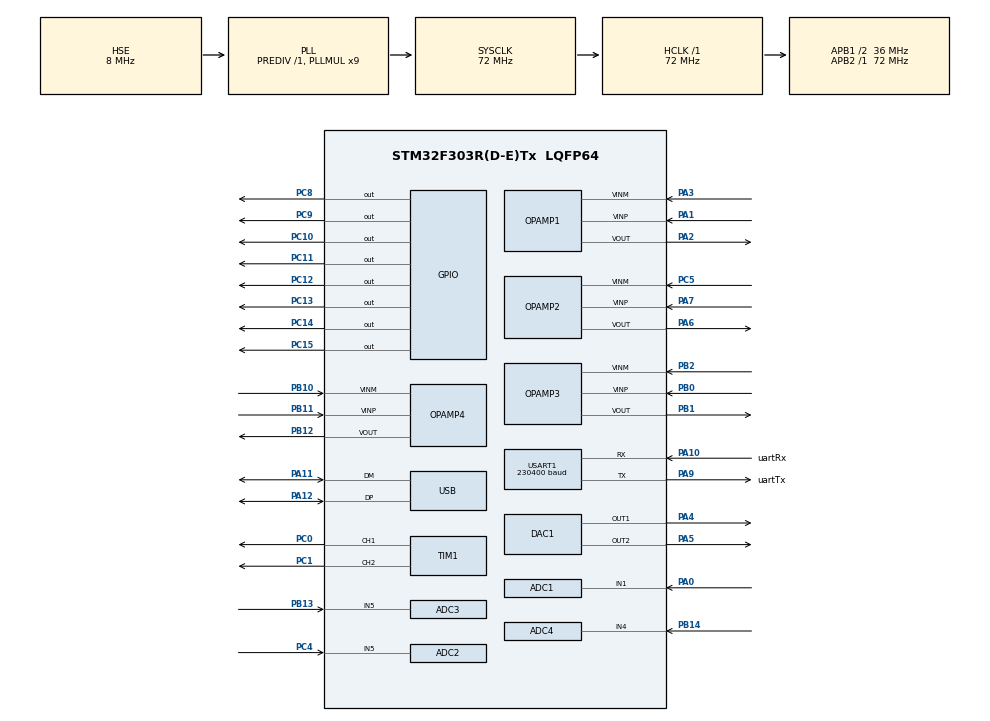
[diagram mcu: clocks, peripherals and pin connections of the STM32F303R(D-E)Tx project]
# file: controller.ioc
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ADC1.AWD1HighThreshold=2500
ADC1.AWD1ITMode=ENABLE
ADC1.AWD1LowThreshold=1500
ADC1.Channel-0\#ChannelRegularConversion=ADC_CHANNEL_3
ADC1.ClockPrescaler=ADC_CLOCK_SYNC_PCLK_DIV1
ADC1.ContinuousConvMode=DISABLE
ADC1.DMAContinuousRequests=ENABLE
ADC1.DataAlign=ADC_DATAALIGN_RIGHT
ADC1.DiscontinuousConvMode=DISABLE
ADC1.EOCSelection=ADC_EOC_SINGLE_CONV
ADC1.EnableAnalogWatchDog1=true
ADC1.EnableAnalogWatchDog2=false
ADC1.EnableAnalogWatchDog3=false
ADC1.EnableInjectedConversion=ENABLE
ADC1.EnableRegularConversion=ENABLE
ADC1.ExternalTrigConv=ADC_EXTERNALTRIGCONV_T3_TRGO
ADC1.ExternalTrigConvEdge=ADC_EXTERNALTRIGCONVEDGE_RISING
ADC1.InjNumberOfConversion=0
ADC1.LowPowerAutoWait=DISABLE
ADC1.NbrOfConversion=1
ADC1.NbrOfConversionFlag=1
ADC1.Offset-0\#ChannelRegularConversion=0
ADC1.OffsetNumber-0\#ChannelRegularConversion=ADC_OFFSET_NONE
ADC1.Overrun=ADC_OVR_DATA_OVERWRITTEN
ADC1.Rank-0\#ChannelRegularConversion=1
ADC1.Resolution=ADC_RESOLUTION_12B
ADC1.SamplingTime-0\#ChannelRegularConversion=ADC_SAMPLETIME_181CYCLES_5
ADC1.ScanConvMode=ADC_SCAN_DISABLE
ADC1.WatchdogChannel=ADC_CHANNEL_3
ADC1.WatchdogMode=ADC_ANALOGWATCHDOG_SINGLE_REG
ADC1.master=1
ADC2.AWD1HighThreshold=2500
ADC2.AWD1ITMode=ENABLE
ADC2.AWD1LowThreshold=1500
ADC2.Channel-0\#ChannelRegularConversion=ADC_CHANNEL_3
ADC2.ClockPrescaler=ADC_CLOCK_SYNC_PCLK_DIV1
ADC2.ContinuousConvMode=DISABLE
ADC2.DMAContinuousRequests=ENABLE
ADC2.DataAlign=ADC_DATAALIGN_RIGHT
ADC2.DiscontinuousConvMode=DISABLE
ADC2.EOCSelection=ADC_EOC_SINGLE_CONV
ADC2.EnableAnalogWatchDog1=true
ADC2.EnableAnalogWatchDog2=false
ADC2.EnableAnalogWatchDog3=false
ADC2.EnableInjectedConversion=ENABLE
ADC2.EnableRegularConversion=ENABLE
ADC2.ExternalTrigConv=ADC_EXTERNALTRIGCONV_T3_TRGO
ADC2.ExternalTrigConvEdge=ADC_EXTERNALTRIGCONVEDGE_RISING
ADC2.InjNumberOfConversion=0
ADC2.LowPowerAutoWait=DISABLE
ADC2.NbrOfConversion=1
ADC2.NbrOfConversionFlag=1
ADC2.Offset-0\#ChannelRegularConversion=0
ADC2.OffsetNumber-0\#ChannelRegularConversion=ADC_OFFSET_NONE
ADC2.Overrun=ADC_OVR_DATA_OVERWRITTEN
ADC2.Rank-0\#ChannelRegularConversion=1
ADC2.Resolution=ADC_RESOLUTION_12B
ADC2.SamplingTime-0\#ChannelRegularConversion=ADC_SAMPLETIME_181CYCLES_5
ADC2.ScanConvMode=ADC_SCAN_DISABLE
ADC2.WatchdogChannel=ADC_CHANNEL_3
ADC2.WatchdogMode=ADC_ANALOGWATCHDOG_SINGLE_REG
ADC3.AWD1HighThreshold=2500
ADC3.AWD1ITMode=ENABLE
ADC3.AWD1LowThreshold=1500
ADC3.Channel-44\#ChannelRegularConversion=ADC_CHANNEL_1
ADC3.ClockPrescaler=ADC_CLOCK_ASYNC_DIV1
ADC3.ContinuousConvMode=DISABLE
ADC3.DMAContinuousRequests=ENABLE
ADC3.DataAlign=ADC_DATAALIGN_RIGHT
ADC3.DiscontinuousConvMode=DISABLE
ADC3.EOCSelection=ADC_EOC_SINGLE_CONV
ADC3.EnableAnalogWatchDog1=true
ADC3.EnableAnalogWatchDog2=false
ADC3.EnableAnalogWatchDog3=false
ADC3.EnableInjectedConversion=ENABLE
ADC3.EnableRegularConversion=ENABLE
ADC3.ExternalTrigConv=ADC_EXTERNALTRIGCONV_T3_TRGO
ADC3.ExternalTrigConvEdge=ADC_EXTERNALTRIGCONVEDGE_RISING
ADC3.InjNumberOfConversion=0
ADC3.LowPowerAutoWait=DISABLE
ADC3.NbrOfConversion=1
ADC3.NbrOfConversionFlag=1
ADC3.Offset-44\#ChannelRegularConversion=0
ADC3.OffsetNumber-44\#ChannelRegularConversion=ADC_OFFSET_NONE
ADC3.Overrun=ADC_OVR_DATA_OVERWRITTEN
ADC3.Rank-44\#ChannelRegularConversion=1
ADC3.Resolution=ADC_RESOLUTION_12B
ADC3.SamplingTime-44\#ChannelRegularConversion=ADC_SAMPLETIME_181CYCLES_5
ADC3.ScanConvMode=ADC_SCAN_DISABLE
ADC3.WatchdogChannel=ADC_CHANNEL_1
ADC3.WatchdogMode=ADC_ANALOGWATCHDOG_SINGLE_REG
ADC3.master=1
ADC4.AWD1HighThreshold=2500
ADC4.AWD1ITMode=ENABLE
ADC4.AWD1LowThreshold=1500
ADC4.Channel-56\#ChannelRegularConversion=ADC_CHANNEL_3
ADC4.ClockPrescaler=ADC_CLOCK_ASYNC_DIV1
ADC4.ContinuousConvMode=DISABLE
ADC4.DMAContinuousRequests=ENABLE
ADC4.DataAlign=ADC_DATAALIGN_RIGHT
ADC4.DiscontinuousConvMode=DISABLE
ADC4.EOCSelection=ADC_EOC_SINGLE_CONV
ADC4.EnableAnalogWatchDog1=true
ADC4.EnableAnalogWatchDog2=false
ADC4.EnableAnalogWatchDog3=false
ADC4.EnableInjectedConversion=ENABLE
ADC4.EnableRegularConversion=ENABLE
ADC4.ExternalTrigConv=ADC_EXTERNALTRIGCONV_T3_TRGO
ADC4.ExternalTrigConvEdge=ADC_EXTERNALTRIGCONVEDGE_RISING
ADC4.InjNumberOfConversion=0
ADC4.LowPowerAutoWait=DISABLE
ADC4.NbrOfConversion=1
ADC4.NbrOfConversionFlag=1
ADC4.Offset-56\#ChannelRegularConversion=0
ADC4.OffsetNumber-56\#ChannelRegularConversion=ADC_OFFSET_NONE
ADC4.Overrun=ADC_OVR_DATA_OVERWRITTEN
ADC4.Rank-56\#ChannelRegularConversion=1
ADC4.Resolution=ADC_RESOLUTION_12B
ADC4.SamplingTime-56\#ChannelRegularConversion=ADC_SAMPLETIME_181CYCLES_5
ADC4.ScanConvMode=ADC_SCAN_DISABLE
ADC4.WatchdogChannel=ADC_CHANNEL_3
ADC4.WatchdogMode=ADC_ANALOGWATCHDOG_SINGLE_REG
Dma.ADC1.6.Direction=DMA_PERIPH_TO_MEMORY
Dma.ADC1.6.Instance=DMA1_Channel1
Dma.ADC1.6.MemDataAlignment=DMA_MDATAALIGN_HALFWORD
Dma.ADC1.6.MemInc=DMA_MINC_ENABLE
Dma.ADC1.6.Mode=DMA_CIRCULAR
Dma.ADC1.6.PeriphDataAlignment=DMA_PDATAALIGN_HALFWORD
Dma.ADC1.6.PeriphInc=DMA_PINC_DISABLE
Dma.ADC1.6.Priority=DMA_PRIORITY_MEDIUM
Dma.ADC2.5.Direction=DMA_PERIPH_TO_MEMORY
Dma.ADC2.5.Instance=DMA2_Channel1
Dma.ADC2.5.MemDataAlignment=DMA_MDATAALIGN_HALFWORD
Dma.ADC2.5.MemInc=DMA_MINC_ENABLE
Dma.ADC2.5.Mode=DMA_CIRCULAR
Dma.ADC2.5.PeriphDataAlignment=DMA_PDATAALIGN_HALFWORD
Dma.ADC2.5.PeriphInc=DMA_PINC_DISABLE
Dma.ADC2.5.Priority=DMA_PRIORITY_MEDIUM
Dma.ADC3.4.Direction=DMA_PERIPH_TO_MEMORY
Dma.ADC3.4.Instance=DMA2_Channel5
Dma.ADC3.4.MemDataAlignment=DMA_MDATAALIGN_HALFWORD
Dma.ADC3.4.MemInc=DMA_MINC_ENABLE
Dma.ADC3.4.Mode=DMA_CIRCULAR
Dma.ADC3.4.PeriphDataAlignment=DMA_PDATAALIGN_HALFWORD
Dma.ADC3.4.PeriphInc=DMA_PINC_DISABLE
Dma.ADC3.4.Priority=DMA_PRIORITY_MEDIUM
Dma.ADC4.3.Direction=DMA_PERIPH_TO_MEMORY
Dma.ADC4.3.Instance=DMA2_Channel2
Dma.ADC4.3.MemDataAlignment=DMA_MDATAALIGN_HALFWORD
Dma.ADC4.3.MemInc=DMA_MINC_ENABLE
Dma.ADC4.3.Mode=DMA_CIRCULAR
Dma.ADC4.3.PeriphDataAlignment=DMA_PDATAALIGN_HALFWORD
Dma.ADC4.3.PeriphInc=DMA_PINC_DISABLE
Dma.ADC4.3.Priority=DMA_PRIORITY_MEDIUM
Dma.MEMTOMEM.0.Direction=DMA_MEMORY_TO_MEMORY
Dma.MEMTOMEM.0.Instance=DMA1_Channel2
Dma.MEMTOMEM.0.MemDataAlignment=DMA_MDATAALIGN_BYTE
Dma.MEMTOMEM.0.MemInc=DMA_MINC_ENABLE
Dma.MEMTOMEM.0.Mode=DMA_NORMAL
Dma.MEMTOMEM.0.PeriphDataAlignment=DMA_PDATAALIGN_BYTE
Dma.MEMTOMEM.0.PeriphInc=DMA_PINC_ENABLE
Dma.MEMTOMEM.0.Priority=DMA_PRIORITY_LOW
Dma.Request0=MEMTOMEM
Dma.Request1=USART1_TX
Dma.Request2=USART1_RX
Dma.Request3=ADC4
Dma.Request4=ADC3
Dma.Request5=ADC2
Dma.Request6=ADC1
Dma.Request7=TIM4_UP
Dma.TIM4_UP.7.Direction=DMA_MEMORY_TO_PERIPH
Dma.TIM4_UP.7.Instance=DMA1_Channel7
Dma.TIM4_UP.7.MemDataAlignment=DMA_MDATAALIGN_BYTE
Dma.TIM4_UP.7.MemInc=DMA_MINC_ENABLE
Dma.TIM4_UP.7.Mode=DMA_NORMAL
Dma.TIM4_UP.7.PeriphDataAlignment=DMA_PDATAALIGN_BYTE
Dma.TIM4_UP.7.PeriphInc=DMA_PINC_DISABLE
Dma.TIM4_UP.7.Priority=DMA_PRIORITY_VERY_HIGH
Dma.USART1_RX.2.Direction=DMA_PERIPH_TO_MEMORY
Dma.USART1_RX.2.Instance=DMA1_Channel5
Dma.USART1_RX.2.MemDataAlignment=DMA_MDATAALIGN_BYTE
Dma.USART1_RX.2.MemInc=DMA_MINC_ENABLE
Dma.USART1_RX.2.Mode=DMA_NORMAL
Dma.USART1_RX.2.PeriphDataAlignment=DMA_PDATAALIGN_BYTE
Dma.USART1_RX.2.PeriphInc=DMA_PINC_DISABLE
Dma.USART1_RX.2.Priority=DMA_PRIORITY_LOW
Dma.USART1_TX.1.Direction=DMA_MEMORY_TO_PERIPH
Dma.USART1_TX.1.Instance=DMA1_Channel4
Dma.USART1_TX.1.MemDataAlignment=DMA_MDATAALIGN_BYTE
Dma.USART1_TX.1.MemInc=DMA_MINC_ENABLE
Dma.USART1_TX.1.Mode=DMA_NORMAL
Dma.USART1_TX.1.PeriphDataAlignment=DMA_PDATAALIGN_BYTE
Dma.USART1_TX.1.PeriphInc=DMA_PINC_DISABLE
Dma.USART1_TX.1.Priority=DMA_PRIORITY_LOW
Mcu.Family=STM32F3
Mcu.Name=STM32F303R(D-E)Tx
Mcu.Package=LQFP64
NVIC.ADC1_2_IRQn=true\:0\:0\:false\:false\:true\:true
NVIC.ADC3_IRQn=true\:0\:0\:false\:false\:true\:true
NVIC.ADC4_IRQn=true\:0\:0\:false\:false\:true\:true
NVIC.DMA1_Channel1_IRQn=true\:0\:0\:false\:false\:true\:false
NVIC.DMA1_Channel4_IRQn=true\:0\:0\:false\:false\:true\:false
NVIC.DMA1_Channel5_IRQn=true\:0\:0\:false\:false\:true\:false
NVIC.DMA1_Channel7_IRQn=true\:0\:0\:false\:false\:true\:false
NVIC.DMA2_Channel1_IRQn=true\:0\:0\:false\:false\:true\:false
NVIC.DMA2_Channel2_IRQn=true\:0\:0\:false\:false\:true\:false
NVIC.DMA2_Channel5_IRQn=true\:0\:0\:false\:false\:true\:false
NVIC.PriorityGroup=NVIC_PRIORITYGROUP_4
NVIC.TIM2_IRQn=true\:0\:0\:false\:false\:true\:true
NVIC.USB_LP_CAN_RX0_IRQn=true\:0\:0\:false\:false\:true\:false
OPAMP1.PgaGain=OPAMP_PGA_GAIN_16
OPAMP2.PgaGain=OPAMP_PGA_GAIN_16
OPAMP3.PgaGain=OPAMP_PGA_GAIN_16
OPAMP4.PgaGain=OPAMP_PGA_GAIN_16
PA0.Mode=IN1-Single-Ended
PA0.Signal=ADC1_IN1
PA1.Mode=PGA Connected
PA1.Signal=OPAMP1_VINP
PA10.GPIO_Label=uartRx
PA10.Mode=Asynchronous
PA10.Signal=USART1_RX
PA11.Mode=Device
PA11.Signal=USB_DM
PA12.Mode=Device
PA12.Signal=USB_DP
PA13.Mode=Serial_Wire
PA13.Signal=SYS_JTMS-SWDIO
PA14.Mode=Serial_Wire
PA14.Signal=SYS_JTCK-SWCLK
PA2.Mode=PGA Connected
PA2.Signal=OPAMP1_VOUT
PA3.Mode=PGA Connected
PA3.Signal=OPAMP1_VINM
PA4.Signal=COMP_DAC11_group
PA5.Signal=COMP_DAC12_group
PA6.GPIO_Mode=GPIO_MODE_ANALOG
PA6.Mode=PGA Connected
PA6.Signal=OPAMP2_VOUT
PA7.Mode=PGA Connected
PA7.Signal=OPAMP2_VINP
PA9.GPIO_Label=uartTx
PA9.Mode=Asynchronous
PA9.Signal=USART1_TX
PB0.Mode=PGA Connected
PB0.Signal=OPAMP3_VINP
PB1.Mode=PGA Connected
PB1.Signal=OPAMP3_VOUT
PB10.Mode=PGA Connected
PB10.Signal=OPAMP4_VINM
PB11.Mode=PGA Connected
PB11.Signal=OPAMP4_VINP
PB12.Mode=PGA Connected
PB12.Signal=OPAMP4_VOUT
PB13.Mode=IN5-Single-Ended
PB13.Signal=ADC3_IN5
PB14.Mode=IN4-Single-Ended
PB14.Signal=ADC4_IN4
PB2.Mode=PGA Connected
PB2.Signal=OPAMP3_VINM
PC0.Signal=S_TIM1_CH1
PC1.Signal=S_TIM1_CH2
PC10.Signal=GPIO_Output
PC11.Signal=GPIO_Output
PC12.Signal=GPIO_Output
PC13.Signal=GPIO_Output
PC14-OSC32_IN.Signal=GPIO_Output
PC15-OSC32_OUT.Signal=GPIO_Output
PC4.Mode=IN5-Single-Ended
PC4.Signal=ADC2_IN5
PC5.Mode=PGA Connected
PC5.Signal=OPAMP2_VINM
PC8.Signal=GPIO_Output
PC9.Signal=GPIO_Output
PF0-OSC_IN.Mode=HSE-External-Oscillator
PF0-OSC_IN.Signal=RCC_OSC_IN
PF1-OSC_OUT.Mode=HSE-External-Oscillator
PF1-OSC_OUT.Signal=RCC_OSC_OUT
ProjectManager.HeapSize=0x200
ProjectManager.StackSize=0x400
ProjectManager.TargetToolchain=SW4STM32
RCC.AHBFreq_Value=72000000
RCC.APB1CLKDivider=RCC_HCLK_DIV2
RCC.APB1Freq_Value=36000000
RCC.APB1TimFreq_Value=72000000
RCC.APB2Freq_Value=72000000
RCC.APB2TimFreq_Value=72000000
RCC.CortexFreq_Value=72000000
RCC.HCLKFreq_Value=72000000
RCC.HSE_VALUE=8000000
RCC.HSI_VALUE=8000000
RCC.LSE_VALUE=32768
RCC.PLLMUL=RCC_PLL_MUL9
RCC.PRESCALERUSB=RCC_USBCLKSOURCE_PLL_DIV1_5
RCC.SYSCLKFreq_VALUE=72000000
RCC.SYSCLKSourceVirtual=RCC_SYSCLKSOURCE_PLLCLK
RCC.USBFreq_Value=48000000
SH.COMP_DAC11_group.0=DAC1_OUT1,DAC_OUT1
SH.COMP_DAC12_group.0=DAC1_OUT2,Enable_DAC_OUT2
SH.S_TIM1_CH1.0=TIM1_CH1,PWM Generation1 CH1
SH.S_TIM1_CH2.0=TIM1_CH2,PWM Generation2 CH2
TIM1.Channel-PWM\ Generation1\ CH1=TIM_CHANNEL_1
TIM1.Channel-PWM\ Generation2\ CH2=TIM_CHANNEL_2
TIM2.AutoReloadPreload=TIM_AUTORELOAD_PRELOAD_ENABLE
TIM2.Period=2211840
TIM2.TIM_MasterOutputTrigger=TIM_TRGO_UPDATE
TIM3.AutoReloadPreload=TIM_AUTORELOAD_PRELOAD_ENABLE
TIM3.Period=1439
TIM3.TIM_MasterOutputTrigger=TIM_TRGO_UPDATE
TIM4.AutoReloadPreload=TIM_AUTORELOAD_PRELOAD_ENABLE
TIM4.Period=28
TIM4.TIM_MasterOutputTrigger=TIM_TRGO_UPDATE
USART1.BaudRate=230400
USART1.VirtualMode-Asynchronous=VM_ASYNC
USART1.WordLength=WORDLENGTH_8B
USB_DEVICE.CLASS_NAME_FS=CDC
USB_DEVICE.VirtualMode=Cdc
USB_DEVICE.VirtualModeFS=Cdc_FS
VP_ADC1_OPAMP_OUT1.Mode=IN-OPAMP1-Single-Ended
VP_ADC2_OPAMP_OUT2.Mode=IN-OPAMP2-Single-Ended
VP_ADC3_OPAMP_OUT3.Mode=IN-OPAMP3-Single-Ended
VP_ADC4_OPAMP_OUT4.Mode=IN-OPAMP4-Single-Ended
VP_TIM1_VS_ClockSourceINT.Mode=Internal
VP_TIM2_VS_ClockSourceINT.Mode=Internal
VP_TIM2_VS_OPM.Mode=OPM_bit
VP_TIM3_VS_ClockSourceINT.Mode=Internal
VP_TIM4_VS_ClockSourceINT.Mode=Internal
VP_USB_DEVICE_VS_USB_DEVICE_CDC_FS.Mode=CDC_FS
board=controller

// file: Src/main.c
/**
  ******************************************************************************
  * @file           : main.c
  * @brief          : Main program body
  ******************************************************************************
  * This notice applies to any and all portions of this file
  * that are not between comment pairs USER CODE BEGIN and
  * USER CODE END. Other portions of this file, whether
  * inserted by the user or by software development tools
  * are owned by their respective copyright owners.
  *
  * Copyright (c) 2018 STMicroelectronics International N.V.
  * All rights reserved.
  *
  * Redistribution and use in source and binary forms, with or without
  * modification, are permitted, provided that the following conditions are met:
  *
  * 1. Redistribution of source code must retain the above copyright notice,
  *    this list of conditions and the following disclaimer.
  * 2. Redistributions in binary form must reproduce the above copyright notice,
  *    this list of conditions and the following disclaimer in the documentation
  *    and/or other materials provided with the distribution.
  * 3. Neither the name of STMicroelectronics nor the names of other
  *    contributors to this software may be used to endorse or promote products
  *    derived from this software without specific written permission.
  * 4. This software, including modifications and/or derivative works of this
  *    software, must execute solely and exclusively on microcontroller or
  *    microprocessor devices manufactured by or for STMicroelectronics.
  * 5. Redistribution and use of this software other than as permitted under
  *    this license is void and will automatically terminate your rights under
  *    this license.
  *
  * THIS SOFTWARE IS PROVIDED BY STMICROELECTRONICS AND CONTRIBUTORS "AS IS"
  * AND ANY EXPRESS, IMPLIED OR STATUTORY WARRANTIES, INCLUDING, BUT NOT
  * LIMITED TO, THE IMPLIED WARRANTIES OF MERCHANTABILITY, FITNESS FOR A
  * PARTICULAR PURPOSE AND NON-INFRINGEMENT OF THIRD PARTY INTELLECTUAL PROPERTY
  * RIGHTS ARE DISCLAIMED TO THE FULLEST EXTENT PERMITTED BY LAW. IN NO EVENT
  * SHALL STMICROELECTRONICS OR CONTRIBUTORS BE LIABLE FOR ANY DIRECT, INDIRECT,
  * INCIDENTAL, SPECIAL, EXEMPLARY, OR CONSEQUENTIAL DAMAGES (INCLUDING, BUT NOT
  * LIMITED TO, PROCUREMENT OF SUBSTITUTE GOODS OR SERVICES; LOSS OF USE, DATA,
  * OR PROFITS; OR BUSINESS INTERRUPTION) HOWEVER CAUSED AND ON ANY THEORY OF
  * LIABILITY, WHETHER IN CONTRACT, STRICT LIABILITY, OR TORT (INCLUDING
  * NEGLIGENCE OR OTHERWISE) ARISING IN ANY WAY OUT OF THE USE OF THIS SOFTWARE,
  * EVEN IF ADVISED OF THE POSSIBILITY OF SUCH DAMAGE.
  *
  ******************************************************************************
  */
#include "main.h"
#include "stm32f3xx_hal.h"
#include "usb_device.h"

/* USER CODE BEGIN Includes */

#include "app.h"

/* USER CODE END Includes */

ADC_HandleTypeDef hadc1;
ADC_HandleTypeDef hadc2;
ADC_HandleTypeDef hadc3;
ADC_HandleTypeDef hadc4;
DMA_HandleTypeDef hdma_adc1;
DMA_HandleTypeDef hdma_adc2;
DMA_HandleTypeDef hdma_adc3;
DMA_HandleTypeDef hdma_adc4;

DAC_HandleTypeDef hdac1;

OPAMP_HandleTypeDef hopamp1;
OPAMP_HandleTypeDef hopamp2;
OPAMP_HandleTypeDef hopamp3;
OPAMP_HandleTypeDef hopamp4;

TIM_HandleTypeDef htim4;
DMA_HandleTypeDef hdma_tim4_up;

UART_HandleTypeDef huart1;
DMA_HandleTypeDef hdma_usart1_tx;
DMA_HandleTypeDef hdma_usart1_rx;

DMA_HandleTypeDef hdma_memtomem_dma1_channel2;

/* USER CODE BEGIN PV */
/* Private variables ---------------------------------------------------------*/

/* USER CODE END PV */

void SystemClock_Config(void);
static void MX_GPIO_Init(void);
static void MX_DMA_Init(void);
static void MX_OPAMP2_Init(void);
static void MX_ADC2_Init(void);
static void MX_TIM3_Init(void);
static void MX_OPAMP4_Init(void);
static void MX_ADC4_Init(void);
static void MX_DAC1_Init(void);
static void MX_OPAMP3_Init(void);
static void MX_ADC1_Init(void);
static void MX_ADC3_Init(void);
static void MX_USART1_UART_Init(void);
static void MX_TIM2_Init(void);
static void MX_TIM4_Init(void);
static void MX_OPAMP1_Init(void);
static void MX_TIM1_Init(void);

/* USER CODE BEGIN PFP */
/* Private function prototypes -----------------------------------------------*/

/* USER CODE END PFP */

int main(void)
{

  /* MCU Configuration----------------------------------------------------------*/

  /* Reset of all peripherals, Initializes the Flash interface and the Systick. */
  HAL_Init();

  /* Configure the system clock */
  SystemClock_Config();

  /* USER CODE BEGIN SysInit */

  __HAL_RCC_SYSCFG_CLK_ENABLE();

  /* USER CODE END SysInit */

  /* Initialize all configured peripherals */
  MX_GPIO_Init();
  MX_DMA_Init();
  MX_OPAMP2_Init();
  MX_ADC2_Init();
  MX_TIM3_Init();
  MX_OPAMP4_Init();
  MX_ADC4_Init();
  MX_DAC1_Init();
  MX_OPAMP3_Init();
  MX_ADC1_Init();
  MX_ADC3_Init();
  MX_USART1_UART_Init();
  MX_TIM2_Init();
  MX_USB_DEVICE_Init();
  MX_TIM4_Init();
  MX_OPAMP1_Init();
  MX_TIM1_Init();
  /* USER CODE BEGIN 2 */

  setup();

  /* USER CODE END 2 */

  /* Infinite loop */
  while (1)
  {

  /* USER CODE BEGIN 3 */

	  loop();

  }
  /* USER CODE END 3 */

}

void SystemClock_Config(void)
{

  RCC_OscInitTypeDef RCC_OscInitStruct;
  RCC_ClkInitTypeDef RCC_ClkInitStruct;
  RCC_PeriphCLKInitTypeDef PeriphClkInit;

    /**Initializes the CPU, AHB and APB busses clocks
    */
  RCC_OscInitStruct.OscillatorType = RCC_OSCILLATORTYPE_HSE;
  RCC_OscInitStruct.HSEState = RCC_HSE_ON;
  RCC_OscInitStruct.HSIState = RCC_HSI_ON;
  RCC_OscInitStruct.PLL.PLLState = RCC_PLL_ON;
  RCC_OscInitStruct.PLL.PLLSource = RCC_PLLSOURCE_HSE;
  RCC_OscInitStruct.PLL.PLLMUL = RCC_PLL_MUL9;
  RCC_OscInitStruct.PLL.PREDIV = RCC_PREDIV_DIV1;
  if (HAL_RCC_OscConfig(&RCC_OscInitStruct) != HAL_OK)
  {
    _Error_Handler(__FILE__, __LINE__);
  }

    /**Initializes the CPU, AHB and APB busses clocks
    */
  RCC_ClkInitStruct.ClockType = RCC_CLOCKTYPE_HCLK|RCC_CLOCKTYPE_SYSCLK
                              |RCC_CLOCKTYPE_PCLK1|RCC_CLOCKTYPE_PCLK2;
  RCC_ClkInitStruct.SYSCLKSource = RCC_SYSCLKSOURCE_PLLCLK;
  RCC_ClkInitStruct.AHBCLKDivider = RCC_SYSCLK_DIV1;
  RCC_ClkInitStruct.APB1CLKDivider = RCC_HCLK_DIV2;
  RCC_ClkInitStruct.APB2CLKDivider = RCC_HCLK_DIV1;

  if (HAL_RCC_ClockConfig(&RCC_ClkInitStruct, FLASH_LATENCY_2) != HAL_OK)
  {
    _Error_Handler(__FILE__, __LINE__);
  }

  PeriphClkInit.PeriphClockSelection = RCC_PERIPHCLK_USB|RCC_PERIPHCLK_USART1
                              |RCC_PERIPHCLK_TIM1|RCC_PERIPHCLK_ADC34
                              |RCC_PERIPHCLK_TIM2|RCC_PERIPHCLK_TIM34;
  PeriphClkInit.Usart1ClockSelection = RCC_USART1CLKSOURCE_PCLK2;
  PeriphClkInit.Adc34ClockSelection = RCC_ADC34PLLCLK_DIV1;
  PeriphClkInit.USBClockSelection = RCC_USBCLKSOURCE_PLL_DIV1_5;
  PeriphClkInit.Tim1ClockSelection = RCC_TIM1CLK_HCLK;
  PeriphClkInit.Tim2ClockSelection = RCC_TIM2CLK_HCLK;
  PeriphClkInit.Tim34ClockSelection = RCC_TIM34CLK_HCLK;
  if (HAL_RCCEx_PeriphCLKConfig(&PeriphClkInit) != HAL_OK)
  {
    _Error_Handler(__FILE__, __LINE__);
  }

    /**Configure the Systick interrupt time
    */
  HAL_SYSTICK_Config(HAL_RCC_GetHCLKFreq()/1000);

    /**Configure the Systick
    */
  HAL_SYSTICK_CLKSourceConfig(SYSTICK_CLKSOURCE_HCLK);

  /* SysTick_IRQn interrupt configuration */
  HAL_NVIC_SetPriority(SysTick_IRQn, 0, 0);
}

/* ADC1 init function */
static void MX_ADC1_Init(void)
{

  ADC_MultiModeTypeDef multimode;
  ADC_AnalogWDGConfTypeDef AnalogWDGConfig;
  ADC_ChannelConfTypeDef sConfig;

    /**Common config
    */
  hadc1.Instance = ADC1;
  hadc1.Init.ClockPrescaler = ADC_CLOCK_SYNC_PCLK_DIV1;
  hadc1.Init.Resolution = ADC_RESOLUTION_12B;
  hadc1.Init.ScanConvMode = ADC_SCAN_DISABLE;
  hadc1.Init.ContinuousConvMode = DISABLE;
  hadc1.Init.DiscontinuousConvMode = DISABLE;
  hadc1.Init.ExternalTrigConvEdge = ADC_EXTERNALTRIGCONVEDGE_RISING;
  hadc1.Init.ExternalTrigConv = ADC_EXTERNALTRIGCONV_T3_TRGO;
  hadc1.Init.DataAlign = ADC_DATAALIGN_RIGHT;
  hadc1.Init.NbrOfConversion = 1;
  hadc1.Init.DMAContinuousRequests = ENABLE;
  hadc1.Init.EOCSelection = ADC_EOC_SINGLE_CONV;
  hadc1.Init.LowPowerAutoWait = DISABLE;
  hadc1.Init.Overrun = ADC_OVR_DATA_OVERWRITTEN;
  if (HAL_ADC_Init(&hadc1) != HAL_OK)
  {
    _Error_Handler(__FILE__, __LINE__);
  }

    /**Configure the ADC multi-mode
    */
  multimode.Mode = ADC_MODE_INDEPENDENT;
  if (HAL_ADCEx_MultiModeConfigChannel(&hadc1, &multimode) != HAL_OK)
  {
    _Error_Handler(__FILE__, __LINE__);
  }

    /**Configure Analog WatchDog 1
    */
  AnalogWDGConfig.WatchdogNumber = ADC_ANALOGWATCHDOG_1;
  AnalogWDGConfig.WatchdogMode = ADC_ANALOGWATCHDOG_SINGLE_REG;
  AnalogWDGConfig.HighThreshold = 2500;
  AnalogWDGConfig.LowThreshold = 1500;
  AnalogWDGConfig.Channel = ADC_CHANNEL_3;
  AnalogWDGConfig.ITMode = ENABLE;
  if (HAL_ADC_AnalogWDGConfig(&hadc1, &AnalogWDGConfig) != HAL_OK)
  {
    _Error_Handler(__FILE__, __LINE__);
  }

    /**Configure Regular Channel
    */
  sConfig.Channel = ADC_CHANNEL_3;
  sConfig.Rank = ADC_REGULAR_RANK_1;
  sConfig.SingleDiff = ADC_SINGLE_ENDED;
  sConfig.SamplingTime = ADC_SAMPLETIME_181CYCLES_5;
  sConfig.OffsetNumber = ADC_OFFSET_NONE;
  sConfig.Offset = 0;
  if (HAL_ADC_ConfigChannel(&hadc1, &sConfig) != HAL_OK)
  {
    _Error_Handler(__FILE__, __LINE__);
  }

}

/* ADC2 init function */
static void MX_ADC2_Init(void)
{

  ADC_AnalogWDGConfTypeDef AnalogWDGConfig;
  ADC_ChannelConfTypeDef sConfig;

    /**Common config
    */
  hadc2.Instance = ADC2;
  hadc2.Init.ClockPrescaler = ADC_CLOCK_SYNC_PCLK_DIV1;
  hadc2.Init.Resolution = ADC_RESOLUTION_12B;
  hadc2.Init.ScanConvMode = ADC_SCAN_DISABLE;
  hadc2.Init.ContinuousConvMode = DISABLE;
  hadc2.Init.DiscontinuousConvMode = DISABLE;
  hadc2.Init.ExternalTrigConvEdge = ADC_EXTERNALTRIGCONVEDGE_RISING;
  hadc2.Init.ExternalTrigConv = ADC_EXTERNALTRIGCONV_T3_TRGO;
  hadc2.Init.DataAlign = ADC_DATAALIGN_RIGHT;
  hadc2.Init.NbrOfConversion = 1;
  hadc2.Init.DMAContinuousRequests = ENABLE;
  hadc2.Init.EOCSelection = ADC_EOC_SINGLE_CONV;
  hadc2.Init.LowPowerAutoWait = DISABLE;
  hadc2.Init.Overrun = ADC_OVR_DATA_OVERWRITTEN;
  if (HAL_ADC_Init(&hadc2) != HAL_OK)
  {
    _Error_Handler(__FILE__, __LINE__);
  }

    /**Configure Analog WatchDog 1
    */
  AnalogWDGConfig.WatchdogNumber = ADC_ANALOGWATCHDOG_1;
  AnalogWDGConfig.WatchdogMode = ADC_ANALOGWATCHDOG_SINGLE_REG;
  AnalogWDGConfig.HighThreshold = 2500;
  AnalogWDGConfig.LowThreshold = 1500;
  AnalogWDGConfig.Channel = ADC_CHANNEL_3;
  AnalogWDGConfig.ITMode = ENABLE;
  if (HAL_ADC_AnalogWDGConfig(&hadc2, &AnalogWDGConfig) != HAL_OK)
  {
    _Error_Handler(__FILE__, __LINE__);
  }

    /**Configure Regular Channel
    */
  sConfig.Channel = ADC_CHANNEL_3;
  sConfig.Rank = ADC_REGULAR_RANK_1;
  sConfig.SingleDiff = ADC_SINGLE_ENDED;
  sConfig.SamplingTime = ADC_SAMPLETIME_181CYCLES_5;
  sConfig.OffsetNumber = ADC_OFFSET_NONE;
  sConfig.Offset = 0;
  if (HAL_ADC_ConfigChannel(&hadc2, &sConfig) != HAL_OK)
  {
    _Error_Handler(__FILE__, __LINE__);
  }

}

/* ADC3 init function */
static void MX_ADC3_Init(void)
{

  ADC_MultiModeTypeDef multimode;
  ADC_AnalogWDGConfTypeDef AnalogWDGConfig;
  ADC_ChannelConfTypeDef sConfig;

    /**Common config
    */
  hadc3.Instance = ADC3;
  hadc3.Init.ClockPrescaler = ADC_CLOCK_ASYNC_DIV1;
  hadc3.Init.Resolution = ADC_RESOLUTION_12B;
  hadc3.Init.ScanConvMode = ADC_SCAN_DISABLE;
  hadc3.Init.ContinuousConvMode = DISABLE;
  hadc3.Init.DiscontinuousConvMode = DISABLE;
  hadc3.Init.ExternalTrigConvEdge = ADC_EXTERNALTRIGCONVEDGE_RISING;
  hadc3.Init.ExternalTrigConv = ADC_EXTERNALTRIGCONV_T3_TRGO;
  hadc3.Init.DataAlign = ADC_DATAALIGN_RIGHT;
  hadc3.Init.NbrOfConversion = 1;
  hadc3.Init.DMAContinuousRequests = ENABLE;
  hadc3.Init.EOCSelection = ADC_EOC_SINGLE_CONV;
  hadc3.Init.LowPowerAutoWait = DISABLE;
  hadc3.Init.Overrun = ADC_OVR_DATA_OVERWRITTEN;
  if (HAL_ADC_Init(&hadc3) != HAL_OK)
  {
    _Error_Handler(__FILE__, __LINE__);
  }

    /**Configure the ADC multi-mode
    */
  multimode.Mode = ADC_MODE_INDEPENDENT;
  if (HAL_ADCEx_MultiModeConfigChannel(&hadc3, &multimode) != HAL_OK)
  {
    _Error_Handler(__FILE__, __LINE__);
  }

    /**Configure Analog WatchDog 1
    */
  AnalogWDGConfig.WatchdogNumber = ADC_ANALOGWATCHDOG_1;
  AnalogWDGConfig.WatchdogMode = ADC_ANALOGWATCHDOG_SINGLE_REG;
  AnalogWDGConfig.HighThreshold = 2500;
  AnalogWDGConfig.LowThreshold = 1500;
  AnalogWDGConfig.Channel = ADC_CHANNEL_1;
  AnalogWDGConfig.ITMode = ENABLE;
  if (HAL_ADC_AnalogWDGConfig(&hadc3, &AnalogWDGConfig) != HAL_OK)
  {
    _Error_Handler(__FILE__, __LINE__);
  }

    /**Configure Regular Channel
    */
  sConfig.Channel = ADC_CHANNEL_1;
  sConfig.Rank = ADC_REGULAR_RANK_1;
  sConfig.SingleDiff = ADC_SINGLE_ENDED;
  sConfig.SamplingTime = ADC_SAMPLETIME_181CYCLES_5;
  sConfig.OffsetNumber = ADC_OFFSET_NONE;
  sConfig.Offset = 0;
  if (HAL_ADC_ConfigChannel(&hadc3, &sConfig) != HAL_OK)
  {
    _Error_Handler(__FILE__, __LINE__);
  }

}

/* ADC4 init function */
static void MX_ADC4_Init(void)
{

  ADC_AnalogWDGConfTypeDef AnalogWDGConfig;
  ADC_ChannelConfTypeDef sConfig;

    /**Common config
    */
  hadc4.Instance = ADC4;
  hadc4.Init.ClockPrescaler = ADC_CLOCK_ASYNC_DIV1;
  hadc4.Init.Resolution = ADC_RESOLUTION_12B;
  hadc4.Init.ScanConvMode = ADC_SCAN_DISABLE;
  hadc4.Init.ContinuousConvMode = DISABLE;
  hadc4.Init.DiscontinuousConvMode = DISABLE;
  hadc4.Init.ExternalTrigConvEdge = ADC_EXTERNALTRIGCONVEDGE_RISING;
  hadc4.Init.ExternalTrigConv = ADC_EXTERNALTRIGCONV_T3_TRGO;
  hadc4.Init.DataAlign = ADC_DATAALIGN_RIGHT;
  hadc4.Init.NbrOfConversion = 1;
  hadc4.Init.DMAContinuousRequests = ENABLE;
  hadc4.Init.EOCSelection = ADC_EOC_SINGLE_CONV;
  hadc4.Init.LowPowerAutoWait = DISABLE;
  hadc4.Init.Overrun = ADC_OVR_DATA_OVERWRITTEN;
  if (HAL_ADC_Init(&hadc4) != HAL_OK)
  {
    _Error_Handler(__FILE__, __LINE__);
  }

    /**Configure Analog WatchDog 1
    */
  AnalogWDGConfig.WatchdogNumber = ADC_ANALOGWATCHDOG_1;
  AnalogWDGConfig.WatchdogMode = ADC_ANALOGWATCHDOG_SINGLE_REG;
  AnalogWDGConfig.HighThreshold = 2500;
  AnalogWDGConfig.LowThreshold = 1500;
  AnalogWDGConfig.Channel = ADC_CHANNEL_3;
  AnalogWDGConfig.ITMode = ENABLE;
  if (HAL_ADC_AnalogWDGConfig(&hadc4, &AnalogWDGConfig) != HAL_OK)
  {
    _Error_Handler(__FILE__, __LINE__);
  }

    /**Configure Regular Channel
    */
  sConfig.Channel = ADC_CHANNEL_3;
  sConfig.Rank = ADC_REGULAR_RANK_1;
  sConfig.SingleDiff = ADC_SINGLE_ENDED;
  sConfig.SamplingTime = ADC_SAMPLETIME_181CYCLES_5;
  sConfig.OffsetNumber = ADC_OFFSET_NONE;
  sConfig.Offset = 0;
  if (HAL_ADC_ConfigChannel(&hadc4, &sConfig) != HAL_OK)
  {
    _Error_Handler(__FILE__, __LINE__);
  }

}

/* DAC1 init function */
static void MX_DAC1_Init(void)
{

  DAC_ChannelConfTypeDef sConfig;

    /**DAC Initialization
    */
  hdac1.Instance = DAC1;
  if (HAL_DAC_Init(&hdac1) != HAL_OK)
  {
    _Error_Handler(__FILE__, __LINE__);
  }

    /**DAC channel OUT1 config
    */
  sConfig.DAC_Trigger = DAC_TRIGGER_NONE;
  sConfig.DAC_OutputBuffer = DAC_OUTPUTBUFFER_ENABLE;
  if (HAL_DAC_ConfigChannel(&hdac1, &sConfig, DAC_CHANNEL_1) != HAL_OK)
  {
    _Error_Handler(__FILE__, __LINE__);
  }

    /**DAC channel OUT2 config
    */
  if (HAL_DAC_ConfigChannel(&hdac1, &sConfig, DAC_CHANNEL_2) != HAL_OK)
  {
    _Error_Handler(__FILE__, __LINE__);
  }

}

/* OPAMP1 init function */
static void MX_OPAMP1_Init(void)
{

  hopamp1.Instance = OPAMP1;
  hopamp1.Init.Mode = OPAMP_PGA_MODE;
  hopamp1.Init.NonInvertingInput = OPAMP_NONINVERTINGINPUT_IO0;
  hopamp1.Init.TimerControlledMuxmode = OPAMP_TIMERCONTROLLEDMUXMODE_DISABLE;
  hopamp1.Init.PgaConnect = OPAMP_PGA_CONNECT_INVERTINGINPUT_IO1;
  hopamp1.Init.PgaGain = OPAMP_PGA_GAIN_4;
  hopamp1.Init.UserTrimming = OPAMP_TRIMMING_FACTORY;
  if (HAL_OPAMP_Init(&hopamp1) != HAL_OK)
  {
    _Error_Handler(__FILE__, __LINE__);
  }

}

/* OPAMP2 init function */
static void MX_OPAMP2_Init(void)
{

  hopamp2.Instance = OPAMP2;
  hopamp2.Init.Mode = OPAMP_PGA_MODE;
  hopamp2.Init.NonInvertingInput = OPAMP_NONINVERTINGINPUT_IO0;
  hopamp2.Init.TimerControlledMuxmode = OPAMP_TIMERCONTROLLEDMUXMODE_DISABLE;
  hopamp2.Init.PgaConnect = OPAMP_PGA_CONNECT_INVERTINGINPUT_IO0;
  hopamp2.Init.PgaGain = OPAMP_PGA_GAIN_4;
  hopamp2.Init.UserTrimming = OPAMP_TRIMMING_FACTORY;
  if (HAL_OPAMP_Init(&hopamp2) != HAL_OK)
  {
    _Error_Handler(__FILE__, __LINE__);
  }

}

/* OPAMP3 init function */
static void MX_OPAMP3_Init(void)
{

  hopamp3.Instance = OPAMP3;
  hopamp3.Init.Mode = OPAMP_PGA_MODE;
  hopamp3.Init.NonInvertingInput = OPAMP_NONINVERTINGINPUT_IO0;
  hopamp3.Init.TimerControlledMuxmode = OPAMP_TIMERCONTROLLEDMUXMODE_DISABLE;
  hopamp3.Init.PgaConnect = OPAMP_PGA_CONNECT_INVERTINGINPUT_IO1;
  hopamp3.Init.PgaGain = OPAMP_PGA_GAIN_4;
  hopamp3.Init.UserTrimming = OPAMP_TRIMMING_FACTORY;
  if (HAL_OPAMP_Init(&hopamp3) != HAL_OK)
  {
    _Error_Handler(__FILE__, __LINE__);
  }

}

/* OPAMP4 init function */
static void MX_OPAMP4_Init(void)
{

  hopamp4.Instance = OPAMP4;
  hopamp4.Init.Mode = OPAMP_PGA_MODE;
  hopamp4.Init.NonInvertingInput = OPAMP_NONINVERTINGINPUT_IO3;
  hopamp4.Init.TimerControlledMuxmode = OPAMP_TIMERCONTROLLEDMUXMODE_DISABLE;
  hopamp4.Init.PgaConnect = OPAMP_PGA_CONNECT_INVERTINGINPUT_IO0;
  hopamp4.Init.PgaGain = OPAMP_PGA_GAIN_4;
  hopamp4.Init.UserTrimming = OPAMP_TRIMMING_FACTORY;
  if (HAL_OPAMP_Init(&hopamp4) != HAL_OK)
  {
    _Error_Handler(__FILE__, __LINE__);
  }

}

/* TIM1 init function */
static void MX_TIM1_Init(void)
{

  LL_TIM_InitTypeDef TIM_InitStruct;
  LL_TIM_OC_InitTypeDef TIM_OC_InitStruct;
  LL_TIM_BDTR_InitTypeDef TIM_BDTRInitStruct;

  LL_GPIO_InitTypeDef GPIO_InitStruct;

  /* Peripheral clock enable */
  LL_APB2_GRP1_EnableClock(LL_APB2_GRP1_PERIPH_TIM1);

  TIM_InitStruct.Prescaler = 0;
  TIM_InitStruct.CounterMode = LL_TIM_COUNTERMODE_UP;
  TIM_InitStruct.Autoreload = 0;
  TIM_InitStruct.ClockDivision = LL_TIM_CLOCKDIVISION_DIV1;
  TIM_InitStruct.RepetitionCounter = 0;
  LL_TIM_Init(TIM1, &TIM_InitStruct);

  LL_TIM_DisableARRPreload(TIM1);

  LL_TIM_SetClockSource(TIM1, LL_TIM_CLOCKSOURCE_INTERNAL);

  LL_TIM_OC_EnablePreload(TIM1, LL_TIM_CHANNEL_CH1);

  TIM_OC_InitStruct.OCMode = LL_TIM_OCMODE_PWM1;
  TIM_OC_InitStruct.OCState = LL_TIM_OCSTATE_DISABLE;
  TIM_OC_InitStruct.OCNState = LL_TIM_OCSTATE_DISABLE;
  TIM_OC_InitStruct.CompareValue = 0;
  TIM_OC_InitStruct.OCPolarity = LL_TIM_OCPOLARITY_HIGH;
  TIM_OC_InitStruct.OCNPolarity = LL_TIM_OCPOLARITY_HIGH;
  TIM_OC_InitStruct.OCIdleState = LL_TIM_OCIDLESTATE_LOW;
  TIM_OC_InitStruct.OCNIdleState = LL_TIM_OCIDLESTATE_LOW;
  LL_TIM_OC_Init(TIM1, LL_TIM_CHANNEL_CH1, &TIM_OC_InitStruct);

  LL_TIM_OC_DisableFast(TIM1, LL_TIM_CHANNEL_CH1);

  LL_TIM_OC_EnablePreload(TIM1, LL_TIM_CHANNEL_CH2);

  TIM_OC_InitStruct.OCState = LL_TIM_OCSTATE_DISABLE;
  TIM_OC_InitStruct.OCNState = LL_TIM_OCSTATE_DISABLE;
  LL_TIM_OC_Init(TIM1, LL_TIM_CHANNEL_CH2, &TIM_OC_InitStruct);

  LL_TIM_OC_DisableFast(TIM1, LL_TIM_CHANNEL_CH2);

  LL_TIM_SetTriggerOutput(TIM1, LL_TIM_TRGO_RESET);

  LL_TIM_SetTriggerOutput2(TIM1, LL_TIM_TRGO2_RESET);

  LL_TIM_DisableMasterSlaveMode(TIM1);

  TIM_BDTRInitStruct.OSSRState = LL_TIM_OSSR_DISABLE;
  TIM_BDTRInitStruct.OSSIState = LL_TIM_OSSI_DISABLE;
  TIM_BDTRInitStruct.LockLevel = LL_TIM_LOCKLEVEL_OFF;
  TIM_BDTRInitStruct.DeadTime = 0;
  TIM_BDTRInitStruct.BreakState = LL_TIM_BREAK_DISABLE;
  TIM_BDTRInitStruct.BreakPolarity = LL_TIM_BREAK_POLARITY_HIGH;
  TIM_BDTRInitStruct.BreakFilter = LL_TIM_BREAK_FILTER_FDIV1;
  TIM_BDTRInitStruct.Break2State = LL_TIM_BREAK2_DISABLE;
  TIM_BDTRInitStruct.Break2Polarity = LL_TIM_BREAK2_POLARITY_HIGH;
  TIM_BDTRInitStruct.Break2Filter = LL_TIM_BREAK2_FILTER_FDIV1;
  TIM_BDTRInitStruct.AutomaticOutput = LL_TIM_AUTOMATICOUTPUT_DISABLE;
  LL_TIM_BDTR_Init(TIM1, &TIM_BDTRInitStruct);

  /**TIM1 GPIO Configuration
  PC0   ------> TIM1_CH1
  PC1   ------> TIM1_CH2
  */
  GPIO_InitStruct.Pin = LL_GPIO_PIN_0|LL_GPIO_PIN_1;
  GPIO_InitStruct.Mode = LL_GPIO_MODE_ALTERNATE;
  GPIO_InitStruct.Speed = LL_GPIO_SPEED_FREQ_LOW;
  GPIO_InitStruct.OutputType = LL_GPIO_OUTPUT_PUSHPULL;
  GPIO_InitStruct.Pull = LL_GPIO_PULL_NO;
  GPIO_InitStruct.Alternate = LL_GPIO_AF_2;
  LL_GPIO_Init(GPIOC, &GPIO_InitStruct);

}

/* TIM2 init function */
static void MX_TIM2_Init(void)
{

  LL_TIM_InitTypeDef TIM_InitStruct;

  /* Peripheral clock enable */
  LL_APB1_GRP1_EnableClock(LL_APB1_GRP1_PERIPH_TIM2);

  /* TIM2 interrupt Init */
  NVIC_SetPriority(TIM2_IRQn, NVIC_EncodePriority(NVIC_GetPriorityGrouping(),0, 0));
  NVIC_EnableIRQ(TIM2_IRQn);

  TIM_InitStruct.Prescaler = 0;
  TIM_InitStruct.CounterMode = LL_TIM_COUNTERMODE_UP;
  TIM_InitStruct.Autoreload = 2211840;
  TIM_InitStruct.ClockDivision = LL_TIM_CLOCKDIVISION_DIV1;
  LL_TIM_Init(TIM2, &TIM_InitStruct);

  LL_TIM_EnableARRPreload(TIM2);

  LL_TIM_SetClockSource(TIM2, LL_TIM_CLOCKSOURCE_INTERNAL);

  LL_TIM_SetOnePulseMode(TIM2, LL_TIM_ONEPULSEMODE_SINGLE);

  LL_TIM_SetTriggerOutput(TIM2, LL_TIM_TRGO_UPDATE);

  LL_TIM_DisableMasterSlaveMode(TIM2);

}

/* TIM3 init function */
static void MX_TIM3_Init(void)
{

  LL_TIM_InitTypeDef TIM_InitStruct;

  /* Peripheral clock enable */
  LL_APB1_GRP1_EnableClock(LL_APB1_GRP1_PERIPH_TIM3);

  TIM_InitStruct.Prescaler = 0;
  TIM_InitStruct.CounterMode = LL_TIM_COUNTERMODE_UP;
  TIM_InitStruct.Autoreload = 1439;
  TIM_InitStruct.ClockDivision = LL_TIM_CLOCKDIVISION_DIV1;
  LL_TIM_Init(TIM3, &TIM_InitStruct);

  LL_TIM_EnableARRPreload(TIM3);

  LL_TIM_SetClockSource(TIM3, LL_TIM_CLOCKSOURCE_INTERNAL);

  LL_TIM_SetTriggerOutput(TIM3, LL_TIM_TRGO_UPDATE);

  LL_TIM_DisableMasterSlaveMode(TIM3);

}

/* TIM4 init function */
static void MX_TIM4_Init(void)
{

  TIM_ClockConfigTypeDef sClockSourceConfig;
  TIM_MasterConfigTypeDef sMasterConfig;

  htim4.Instance = TIM4;
  htim4.Init.Prescaler = 0;
  htim4.Init.CounterMode = TIM_COUNTERMODE_UP;
  htim4.Init.Period = 28;
  htim4.Init.ClockDivision = TIM_CLOCKDIVISION_DIV1;
  htim4.Init.AutoReloadPreload = TIM_AUTORELOAD_PRELOAD_ENABLE;
  if (HAL_TIM_Base_Init(&htim4) != HAL_OK)
  {
    _Error_Handler(__FILE__, __LINE__);
  }

  sClockSourceConfig.ClockSource = TIM_CLOCKSOURCE_INTERNAL;
  if (HAL_TIM_ConfigClockSource(&htim4, &sClockSourceConfig) != HAL_OK)
  {
    _Error_Handler(__FILE__, __LINE__);
  }

  sMasterConfig.MasterOutputTrigger = TIM_TRGO_UPDATE;
  sMasterConfig.MasterSlaveMode = TIM_MASTERSLAVEMODE_DISABLE;
  if (HAL_TIMEx_MasterConfigSynchronization(&htim4, &sMasterConfig) != HAL_OK)
  {
    _Error_Handler(__FILE__, __LINE__);
  }

}

/* USART1 init function */
static void MX_USART1_UART_Init(void)
{

  huart1.Instance = USART1;
  huart1.Init.BaudRate = 230400;
  huart1.Init.WordLength = UART_WORDLENGTH_8B;
  huart1.Init.StopBits = UART_STOPBITS_1;
  huart1.Init.Parity = UART_PARITY_NONE;
  huart1.Init.Mode = UART_MODE_TX_RX;
  huart1.Init.HwFlowCtl = UART_HWCONTROL_NONE;
  huart1.Init.OverSampling = UART_OVERSAMPLING_16;
  huart1.Init.OneBitSampling = UART_ONE_BIT_SAMPLE_DISABLE;
  huart1.AdvancedInit.AdvFeatureInit = UART_ADVFEATURE_NO_INIT;
  if (HAL_UART_Init(&huart1) != HAL_OK)
  {
    _Error_Handler(__FILE__, __LINE__);
  }

}

static void MX_DMA_Init(void)
{
  /* DMA controller clock enable */
  __HAL_RCC_DMA1_CLK_ENABLE();
  __HAL_RCC_DMA2_CLK_ENABLE();

  /* Configure DMA request hdma_memtomem_dma1_channel2 on DMA1_Channel2 */
  hdma_memtomem_dma1_channel2.Instance = DMA1_Channel2;
  hdma_memtomem_dma1_channel2.Init.Direction = DMA_MEMORY_TO_MEMORY;
  hdma_memtomem_dma1_channel2.Init.PeriphInc = DMA_PINC_ENABLE;
  hdma_memtomem_dma1_channel2.Init.MemInc = DMA_MINC_ENABLE;
  hdma_memtomem_dma1_channel2.Init.PeriphDataAlignment = DMA_PDATAALIGN_BYTE;
  hdma_memtomem_dma1_channel2.Init.MemDataAlignment = DMA_MDATAALIGN_BYTE;
  hdma_memtomem_dma1_channel2.Init.Mode = DMA_NORMAL;
  hdma_memtomem_dma1_channel2.Init.Priority = DMA_PRIORITY_LOW;
  if (HAL_DMA_Init(&hdma_memtomem_dma1_channel2) != HAL_OK)
  {
    _Error_Handler(__FILE__, __LINE__);
  }

  /* DMA interrupt init */
  /* DMA1_Channel1_IRQn interrupt configuration */
  HAL_NVIC_SetPriority(DMA1_Channel1_IRQn, 0, 0);
  HAL_NVIC_EnableIRQ(DMA1_Channel1_IRQn);
  /* DMA1_Channel4_IRQn interrupt configuration */
  HAL_NVIC_SetPriority(DMA1_Channel4_IRQn, 0, 0);
  HAL_NVIC_EnableIRQ(DMA1_Channel4_IRQn);
  /* DMA1_Channel5_IRQn interrupt configuration */
  HAL_NVIC_SetPriority(DMA1_Channel5_IRQn, 0, 0);
  HAL_NVIC_EnableIRQ(DMA1_Channel5_IRQn);
  /* DMA1_Channel7_IRQn interrupt configuration */
  HAL_NVIC_SetPriority(DMA1_Channel7_IRQn, 0, 0);
  HAL_NVIC_EnableIRQ(DMA1_Channel7_IRQn);
  /* DMA2_Channel1_IRQn interrupt configuration */
  HAL_NVIC_SetPriority(DMA2_Channel1_IRQn, 0, 0);
  HAL_NVIC_EnableIRQ(DMA2_Channel1_IRQn);
  /* DMA2_Channel2_IRQn interrupt configuration */
  HAL_NVIC_SetPriority(DMA2_Channel2_IRQn, 0, 0);
  HAL_NVIC_EnableIRQ(DMA2_Channel2_IRQn);
  /* DMA2_Channel5_IRQn interrupt configuration */
  HAL_NVIC_SetPriority(DMA2_Channel5_IRQn, 0, 0);
  HAL_NVIC_EnableIRQ(DMA2_Channel5_IRQn);

}

/** Configure pins as
        * Analog
        * Input
        * Output
        * EVENT_OUT
        * EXTI
*/
static void MX_GPIO_Init(void)
{

  GPIO_InitTypeDef GPIO_InitStruct;

  /* GPIO Ports Clock Enable */
  __HAL_RCC_GPIOC_CLK_ENABLE();
  __HAL_RCC_GPIOF_CLK_ENABLE();
  __HAL_RCC_GPIOA_CLK_ENABLE();
  __HAL_RCC_GPIOB_CLK_ENABLE();

  /*Configure GPIO pin Output Level */
  HAL_GPIO_WritePin(GPIOC, GPIO_PIN_13|GPIO_PIN_14|GPIO_PIN_15|GPIO_PIN_8
                          |GPIO_PIN_9|GPIO_PIN_10|GPIO_PIN_11|GPIO_PIN_12, GPIO_PIN_RESET);

  /*Configure GPIO pins : PC13 PC14 PC15 PC8
                           PC9 PC10 PC11 PC12 */
  GPIO_InitStruct.Pin = GPIO_PIN_13|GPIO_PIN_14|GPIO_PIN_15|GPIO_PIN_8
                          |GPIO_PIN_9|GPIO_PIN_10|GPIO_PIN_11|GPIO_PIN_12;
  GPIO_InitStruct.Mode = GPIO_MODE_OUTPUT_PP;
  GPIO_InitStruct.Pull = GPIO_NOPULL;
  GPIO_InitStruct.Speed = GPIO_SPEED_FREQ_LOW;
  HAL_GPIO_Init(GPIOC, &GPIO_InitStruct);

}

void _Error_Handler(char *file, int line)
{
  while(1)
  {
  }
}

/************************ (C) COPYRIGHT STMicroelectronics *****END OF FILE****/
